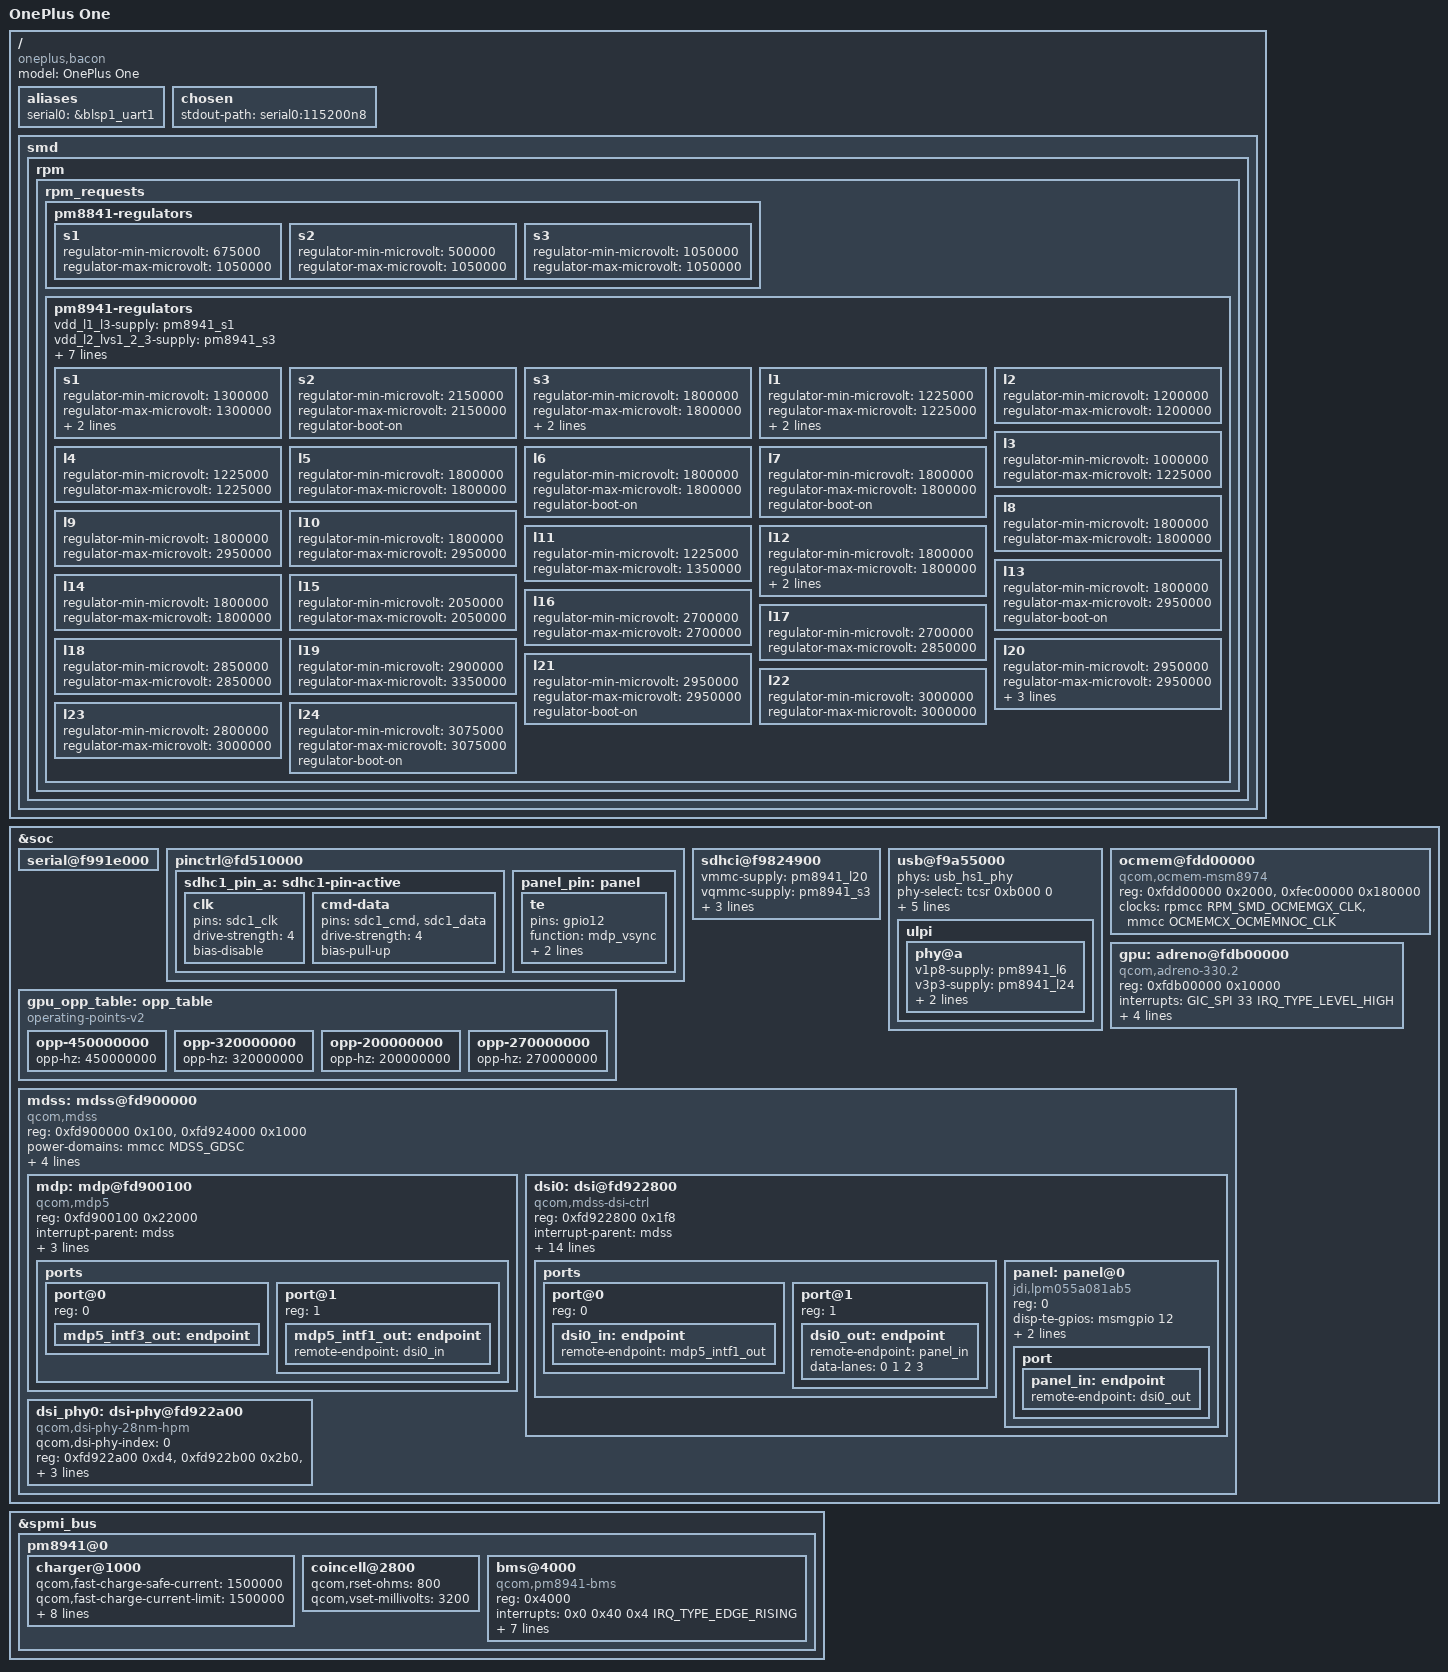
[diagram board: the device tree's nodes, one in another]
// SPDX-License-Identifier: GPL-2.0
#include "qcom-msm8974.dtsi"
#include "qcom-pm8841.dtsi"
#include "qcom-pm8941.dtsi"
#include <dt-bindings/gpio/gpio.h>
#include <dt-bindings/input/input.h>
#include <dt-bindings/pinctrl/qcom,pmic-gpio.h>
#include <dt-bindings/clock/qcom,mmcc-msm8974.h>

/ {
	model = "OnePlus One";
	compatible = "oneplus,bacon", "qcom,msm8974";

	aliases {
		serial0 = &blsp1_uart1;
	};

	chosen {
		stdout-path = "serial0:115200n8";
	};

	smd {
		rpm {
			rpm_requests {
				pm8841-regulators {
					s1 {
						regulator-min-microvolt = <675000>;
						regulator-max-microvolt = <1050000>;
					};

					s2 {
						regulator-min-microvolt = <500000>;
						regulator-max-microvolt = <1050000>;
					};

					s3 {
						regulator-min-microvolt = <1050000>;
						regulator-max-microvolt = <1050000>;
					};
				};

				pm8941-regulators {
					vdd_l1_l3-supply = <&pm8941_s1>;
					vdd_l2_lvs1_2_3-supply = <&pm8941_s3>;
					vdd_l4_l11-supply = <&pm8941_s1>;
					vdd_l5_l7-supply = <&pm8941_s2>;
					vdd_l6_l12_l14_l15-supply = <&pm8941_s2>;
					vdd_l8_l16_l18_l19-supply = <&vreg_vph_pwr>;
					vdd_l9_l10_l17_l22-supply = <&vreg_boost>;
					vdd_l13_l20_l23_l24-supply = <&vreg_boost>;
					vdd_l21-supply = <&vreg_boost>;

					s1 {
						regulator-min-microvolt = <1300000>;
						regulator-max-microvolt = <1300000>;

						regulator-always-on;
						regulator-boot-on;
					};

					s2 {
						regulator-min-microvolt = <2150000>;
						regulator-max-microvolt = <2150000>;

						regulator-boot-on;
					};

					s3 {
						regulator-min-microvolt = <1800000>;
						regulator-max-microvolt = <1800000>;

						regulator-always-on;
						regulator-boot-on;
					};

					l1 {
						regulator-min-microvolt = <1225000>;
						regulator-max-microvolt = <1225000>;

						regulator-always-on;
						regulator-boot-on;
					};

					l2 {
						regulator-min-microvolt = <1200000>;
						regulator-max-microvolt = <1200000>;
					};

					l3 {
						regulator-min-microvolt = <1000000>;
						regulator-max-microvolt = <1225000>;
					};

					l4 {
						regulator-min-microvolt = <1225000>;
						regulator-max-microvolt = <1225000>;
					};

					l5 {
						regulator-min-microvolt = <1800000>;
						regulator-max-microvolt = <1800000>;
					};

					l6 {
						regulator-min-microvolt = <1800000>;
						regulator-max-microvolt = <1800000>;

						regulator-boot-on;
					};

					l7 {
						regulator-min-microvolt = <1800000>;
						regulator-max-microvolt = <1800000>;

						regulator-boot-on;
					};

					l8 {
						regulator-min-microvolt = <1800000>;
						regulator-max-microvolt = <1800000>;
					};

					l9 {
						regulator-min-microvolt = <1800000>;
						regulator-max-microvolt = <2950000>;
					};

					l10 {
						regulator-min-microvolt = <1800000>;
						regulator-max-microvolt = <2950000>;
					};

					l11 {
						regulator-min-microvolt = <1225000>;
						regulator-max-microvolt = <1350000>;
					};

					l12 {
						regulator-min-microvolt = <1800000>;
						regulator-max-microvolt = <1800000>;

						regulator-always-on;
						regulator-boot-on;
					};

					l13 {
						regulator-min-microvolt = <1800000>;
						regulator-max-microvolt = <2950000>;

						regulator-boot-on;
					};

					l14 {
						regulator-min-microvolt = <1800000>;
						regulator-max-microvolt = <1800000>;
					};

					l15 {
						regulator-min-microvolt = <2050000>;
						regulator-max-microvolt = <2050000>;
					};

					l16 {
						regulator-min-microvolt = <2700000>;
						regulator-max-microvolt = <2700000>;
					};

					l17 {
						regulator-min-microvolt = <2700000>;
						regulator-max-microvolt = <2850000>;
					};

					l18 {
						regulator-min-microvolt = <2850000>;
						regulator-max-microvolt = <2850000>;
					};

					l19 {
						regulator-min-microvolt = <2900000>;
						regulator-max-microvolt = <3350000>;
					};

					l20 {
						regulator-min-microvolt = <2950000>;
						regulator-max-microvolt = <2950000>;

						regulator-boot-on;

						regulator-system-load = <200000>;
						regulator-allow-set-load;
					};

					l21 {
						regulator-min-microvolt = <2950000>;
						regulator-max-microvolt = <2950000>;

						regulator-boot-on;
					};

					l22 {
						regulator-min-microvolt = <3000000>;
						regulator-max-microvolt = <3000000>;
					};

					l23 {
						regulator-min-microvolt = <2800000>;
						regulator-max-microvolt = <3000000>;
					};

					l24 {
						regulator-min-microvolt = <3075000>;
						regulator-max-microvolt = <3075000>;

						regulator-boot-on;
					};
				};
			};
		};
	};
};

&soc {
	serial@f991e000 {
		status = "ok";
	};

	pinctrl@fd510000 {
		sdhc1_pin_a: sdhc1-pin-active {
			clk {
				pins = "sdc1_clk";
				drive-strength = <4>;
				bias-disable;
			};

			cmd-data {
				pins = "sdc1_cmd", "sdc1_data";
				drive-strength = <4>;
				bias-pull-up;
			};
		};

		panel_pin: panel {
			te {
				pins = "gpio12";
				function = "mdp_vsync";

				drive-strength = <2>;
				bias-disable;
			};
		};
	};

	sdhci@f9824900 {
		status = "ok";

		vmmc-supply = <&pm8941_l20>;
		vqmmc-supply = <&pm8941_s3>;

		bus-width = <8>;
		non-removable;

		pinctrl-names = "default";
		pinctrl-0 = <&sdhc1_pin_a>;
	};

        usb@f9a55000 {
                status = "ok";

                phys = <&usb_hs1_phy>;
                phy-select = <&tcsr 0xb000 0>;
                extcon = <&smbb>, <&usb_id>;
                vbus-supply = <&chg_otg>;

                hnp-disable;
                srp-disable;
                adp-disable;

                ulpi {
                        phy@a {
                                status = "ok";

                                v1p8-supply = <&pm8941_l6>;
                                v3p3-supply = <&pm8941_l24>;

                                extcon = <&smbb>;
                                qcom,init-seq = /bits/ 8 <0x1 0x64>;
                        };
                };
        };

	ocmem@fdd00000 {
		compatible = "qcom,ocmem-msm8974";
		// "ocmem_ctrl_physical" should be the registers, "ocmem_physical"
		// is (I think) letting CPU read ocmem directly..

		reg = <0xfdd00000 0x2000>,
		      <0xfec00000 0x180000>;
		reg-names = "ocmem_ctrl_physical",
			"ocmem_physical";

		clocks = <&rpmcc RPM_SMD_OCMEMGX_CLK>,
		     <&mmcc OCMEMCX_OCMEMNOC_CLK>;
		clock-names = "core_clk", "iface_clk";
	};

	gpu_opp_table: opp_table {
		compatible = "operating-points-v2";

		/*
		opp-533000000 {
			opp-hz = /bits/ 64 <533000000>;
		};
		opp-27000000 {
			opp-hz = /bits/ 64 <27000000>;
		};
		*/
		opp-450000000 {
			opp-hz = /bits/ 64 <450000000>;
		};
		opp-320000000 {
			opp-hz = /bits/ 64 <320000000>;
		};
		opp-200000000 {
			opp-hz = /bits/ 64 <200000000>;
		};
		opp-270000000 {
			opp-hz = /bits/ 64 <270000000>;
		};
	};

	gpu: adreno@fdb00000 {
		compatible = "qcom,adreno-330.2", "qcom,adreno";
		reg = <0xfdb00000 0x10000>;
		reg-names = "kgsl_3d0_reg_memory";
		interrupts = <GIC_SPI 33 IRQ_TYPE_LEVEL_HIGH>;
		interrupt-names = "kgsl_3d0_irq";
		clock-names = "core",
			      "iface",
			      "mem_iface";
		clocks = <&mmcc OXILI_GFX3D_CLK>,
			 <&mmcc OXILICX_AHB_CLK>,
			 <&mmcc OXILICX_AXI_CLK>;

		power-domains = <&mmcc OXILICX_GDSC>;
		operating-points-v2 = <&gpu_opp_table>;

		// iommus = <&gpu_iommu 0>;
	};

	mdss: mdss@fd900000 {
		compatible = "qcom,mdss";
		reg = <0xfd900000 0x100>,
		      <0xfd924000 0x1000>;
		reg-names = "mdss_phys", "vbif_phys";

		power-domains = <&mmcc MDSS_GDSC>;

		clocks = <&mmcc MDSS_AHB_CLK>,
		     <&mmcc MDSS_AXI_CLK>,
		     <&mmcc MDSS_VSYNC_CLK>;
		clock-names = "iface",
			  "bus",
			  "vsync";

		interrupts = <GIC_SPI 72 0>;

		interrupt-controller;
		#interrupt-cells = <1>;

		#address-cells = <1>;
		#size-cells = <1>;
		ranges;

		mdp: mdp@fd900100 {
			compatible = "qcom,mdp5";
			reg = <0xfd900100 0x22000>;
			reg-names = "mdp_phys";

			interrupt-parent = <&mdss>;
			interrupts = <0 0>;

			clocks =<&mmcc MDSS_AHB_CLK>,
				<&mmcc MDSS_AXI_CLK>,
				<&mmcc MDSS_MDP_CLK>,
				<&mmcc MDSS_VSYNC_CLK>;
			clock-names =   "iface",
					"bus",
					"core",
					"vsync";

			// iommus = <&mdp_iommu 0>;

			ports {
				#address-cells = <1>;
				#size-cells = <0>;

				port@0 {
					reg = <0>;
					mdp5_intf3_out: endpoint {
					};
				};

				port@1 {
					reg = <1>;
					mdp5_intf1_out: endpoint {
						remote-endpoint = <&dsi0_in>;
					};
				};
			};
		};

		dsi0: dsi@fd922800 {
		    compatible = "qcom,mdss-dsi-ctrl";
		    reg = <0xfd922800 0x1f8>;
		    reg-names = "dsi_ctrl";

		    interrupt-parent = <&mdss>;
		    interrupts = <4 0>;

		    assigned-clocks =
			     <&mmcc BYTE0_CLK_SRC>,
			     <&mmcc PCLK0_CLK_SRC>;
		    assigned-clock-parents =
			     <&dsi_phy0 0>,
			     <&dsi_phy0 1>;

		    clocks = 	<&mmcc MDSS_MDP_CLK>,
				<&mmcc MDSS_AHB_CLK>,
				<&mmcc MDSS_AXI_CLK>,
				<&mmcc MDSS_BYTE0_CLK>,
				<&mmcc MDSS_PCLK0_CLK>,
				<&mmcc MDSS_ESC0_CLK>,
				<&mmcc MMSS_MISC_AHB_CLK>,
				<&mmcc MMSS_S0_AXI_CLK>,
				<&mmcc MMSS_MMSSNOC_AXI_CLK>;
		    clock-names = "mdp_core",
			      "iface",
			      "bus",
			      "byte",
			      "pixel",
			      "core",
			      "core_mmss",
			      "s0_axi",
			      "mmssnoc";

		    phys = <&dsi_phy0>;
		    phy-names ="dsi-phy";

		    vdda-supply = <&pm8941_l2>;
		    vdd-supply = <&pm8941_lvs3>;
		    vddio-supply = <&pm8941_l12>;

		    #address-cells = <1>;
		    #size-cells = <0>;

		    ports {
			#address-cells = <1>;
			#size-cells = <0>;

			port@0 {
			    reg = <0>;
			    dsi0_in: endpoint {
				// FIXME: could this have to do with our update problem?
				remote-endpoint = <&mdp5_intf1_out>;
			    };
			};

			port@1 {
			    reg = <1>;
			    dsi0_out: endpoint {
				remote-endpoint = <&panel_in>;
				data-lanes = <0 1 2 3>;
			    };
			};
		    };

		    panel: panel@0 {
			reg = <0>;
			compatible = "jdi,lpm055a081ab5";

			// backlight?, reset?, enable?

			disp-te-gpios = <&msmgpio 12 0>;
			enable-gpios = <&msmgpio 58 0>;

			pinctrl-names = "default";
			pinctrl-0 = <&panel_pin>;

			port {
			    panel_in: endpoint {
				remote-endpoint = <&dsi0_out>;
			    };
			};
		    };
		};

		dsi_phy0: dsi-phy@fd922a00 {
		    compatible = "qcom,dsi-phy-28nm-hpm";
		    qcom,dsi-phy-index = <0>;
		    reg-names =
			"dsi_pll",
			"dsi_phy",
			"dsi_phy_regulator";
		    reg = <0xfd922a00 0xd4>,
			  <0xfd922b00 0x2b0>,
			  <0xfd922d80 0x30>;

		    #clock-cells = <1>;

		    clocks = <&mmcc MDSS_AHB_CLK>;
		    clock-names = "iface";

		    vddio-supply = <&pm8941_l12>;

		    #phy-cells = <0>;
		};
	};

	// look at the castor dts in the wip/8974-iommu branch of andersson/kernel on github
	// that fork is old, look at flto/linux
	// flto uses the lge-nexus5-hammerhead device to test with
};

&spmi_bus {
	pm8941@0 {
		charger@1000 {
			qcom,fast-charge-safe-current = <1500000>;
			qcom,fast-charge-current-limit = <1500000>;
			qcom,dc-current-limit = <1800000>;
			qcom,fast-charge-safe-voltage = <4400000>;
			qcom,fast-charge-high-threshold-voltage = <4350000>;
			qcom,fast-charge-low-threshold-voltage = <3400000>;
			qcom,auto-recharge-threshold-voltage = <4200000>;
			qcom,minimum-input-voltage = <4400000>;
		};

		coincell@2800 {
			status = "ok";
			qcom,rset-ohms = <800>;
			qcom,vset-millivolts = <3200>;
		};

		bms@4000 {
			compatible = "qcom,pm8941-bms";
			reg = <0x4000>;
			interrupts = <0x0 0x40 0x4 IRQ_TYPE_EDGE_RISING>;
			interrupt-names = "ocv_thr";

			fcc-temp-legend = /bits/ 8 <(-20) 0 25 40 60>;
			fcc-lut = /bits/ 16 <3030 3033 3037 3035 3031>;
			
			ocv-capacity-legend = /bits/ 8 <
							100 95 90 85 80
							75 70 65 60 55
							50 45 40 35 30
							25 20 16 13 11
							10 9 8 7 6
							5 4 3 2 1
							0>;
			ocv-temp-legend = /bits/ 8 <(-20) 0 25 40 60>;
			ocv-lut = /bits/ 16 <
				4191 4188 4183 4179 4174
				4106 4125 4127 4125 4121
				4046 4082 4082 4080 4077
				3966 4038 4044 4040 4035
				3922 3983 3994 3998 3997
				3886 3949 3966 3966 3962
				3856 3908 3937 3935 3931
				3832 3875 3908 3907 3903
				3814 3847 3874 3878 3875
				3799 3826 3831 3832 3830
				3787 3807 3811 3811 3809
				3775 3793 3795 3795 3793
				3764 3782 3783 3783 3781
				3752 3775 3773 3772 3769
				3739 3768 3766 3762 3755
				3725 3756 3756 3747 3733
				3710 3732 3734 3725 3711
				3696 3707 3705 3697 3684
				3681 3695 3686 3678 3667
				3667 3690 3684 3676 3665
				3658 3688 3683 3675 3664
				3646 3685 3681 3674 3663
				3631 3682 3679 3673 3660
				3612 3677 3676 3669 3655
				3589 3667 3666 3660 3639
				3560 3643 3636 3630 3599
				3523 3600 3586 3581 3546
				3474 3537 3518 3516 3477
				3394 3446 3425 3427 3379
				3257 3306 3273 3283 3213
				3000 3000 3000 3000 3000>;
		};

	};
};
